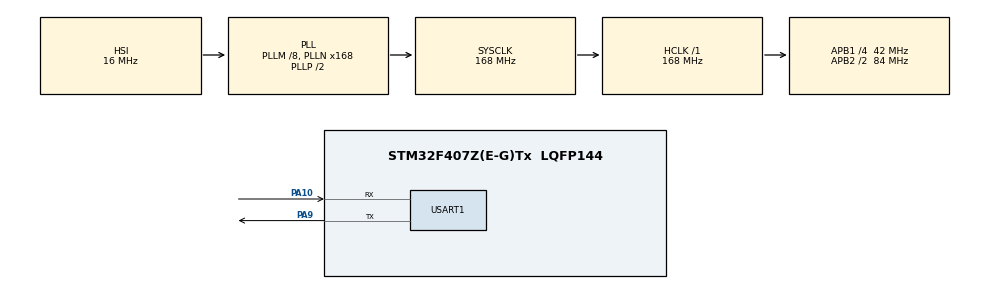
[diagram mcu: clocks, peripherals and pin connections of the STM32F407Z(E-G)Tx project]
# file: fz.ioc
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FREERTOS.BinarySemaphores01=ShellReadSem,Dynamic,NULL
FREERTOS.Mutexes01=ShellTxMut,Dynamic,NULL
FREERTOS.Queues01=UartRx,8,uint8_t,NULL,Dynamic,NULL,NULL
FREERTOS.Tasks01=defaultTask,0,128,StartDefaultTask,Default,NULL,Dynamic,NULL,NULL;ShellRead,-3,128,ShellReadEntry,Default,NULL,Dynamic,NULL,NULL
FREERTOS.configUSE_ALTERNATIVE_API=0
Mcu.Family=STM32F4
Mcu.Name=STM32F407Z(E-G)Tx
Mcu.Package=LQFP144
NVIC.PriorityGroup=NVIC_PRIORITYGROUP_4
NVIC.USART1_IRQn=true\:5\:0\:false\:false\:true\:true
PA10.Mode=Asynchronous
PA10.Signal=USART1_RX
PA9.Mode=Asynchronous
PA9.Signal=USART1_TX
PH0-OSC_IN.Mode=HSE-External-Oscillator
PH0-OSC_IN.Signal=RCC_OSC_IN
PH1-OSC_OUT.Mode=HSE-External-Oscillator
PH1-OSC_OUT.Signal=RCC_OSC_OUT
ProjectManager.HeapSize=0x200
ProjectManager.StackSize=0x400
ProjectManager.TargetToolchain=EWARM
RCC.48MHZClocksFreq_Value=84000000
RCC.AHBCLKDivider=RCC_SYSCLK_DIV1
RCC.AHBFreq_Value=168000000
RCC.APB1CLKDivider=RCC_HCLK_DIV4
RCC.APB1Freq_Value=42000000
RCC.APB1TimFreq_Value=84000000
RCC.APB2CLKDivider=RCC_HCLK_DIV2
RCC.APB2Freq_Value=84000000
RCC.APB2TimFreq_Value=168000000
RCC.ClockTypeHCLK=RCC_CLOCKTYPE_HCLK
RCC.ClockTypePCLK1=RCC_CLOCKTYPE_PCLK1
RCC.ClockTypePCLK2=RCC_CLOCKTYPE_PCLK2
RCC.ClockTypeSysClk=RCC_CLOCKTYPE_SYSCLK
RCC.CortexFreq_Value=168000000
RCC.Cortex_Div=SYSTICK_CLKSOURCE_HCLK
RCC.EnableExtClockForI2S=false
RCC.EnableHSE=true
RCC.EnableHSERTCDevisor=false
RCC.EnableLSE=false
RCC.EnableLSERTC=false
RCC.ExtClockEnable=false
RCC.HCLKFreq_Value=168000000
RCC.HSEState=RCC_HSE_ON
RCC.HSE_VALUE=8000000
RCC.HSIState=RCC_HSI_ON
RCC.HSI_VALUE=16000000
RCC.I2SEnable=false
RCC.IWDGEnable=false
RCC.LSE_VALUE=32768
RCC.LSIState=RCC_LSI_OFF
RCC.MCO1OutPutEnable=false
RCC.MCO2OutPutEnable=false
RCC.OscillatorTypeHSI=RCC_OSCILLATORTYPE_HSI
RCC.PLLM=8
RCC.PLLN=168
RCC.PLLP=RCC_PLLP_DIV2
RCC.PLLSource=RCC_PLLSOURCE_HSI
RCC.PLLState=RCC_PLL_ON
RCC.RCC_MCODiv1=RCC_MCODIV_1
RCC.RCC_MCODiv2=RCC_MCODIV_1
RCC.RCC_RTC_Clock_Source_FROM_HSE=RCC_RTCCLKSOURCE_HSE_DIV2
RCC.RNGEnable=false
RCC.RTCEnable=false
RCC.SDIOEnable=false
RCC.SYSCLKFreq_VALUE=168000000
RCC.SYSCLKSource=RCC_SYSCLKSOURCE_PLLCLK
RCC.USBFSEnable=false
RCC.USBHSEnable=false
RCC.VCOOutputFreq_Value=336000000
USART1.HwFlowCtl-Asynchronous=UART_HWCONTROL_NONE
USART1.VirtualMode=VM_ASYNC
VP_FREERTOS_VS_ENABLE.Mode=Enabled
board=fz

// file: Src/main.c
/**
  ******************************************************************************
  * File Name          : main.c
  * Description        : Main program body
  ******************************************************************************
  *
  * Copyright (c) 2017 STMicroelectronics International N.V.
  * All rights reserved.
  *
  * Redistribution and use in source and binary forms, with or without
  * modification, are permitted, provided that the following conditions are met:
  *
  * 1. Redistribution of source code must retain the above copyright notice,
  *    this list of conditions and the following disclaimer.
  * 2. Redistributions in binary form must reproduce the above copyright notice,
  *    this list of conditions and the following disclaimer in the documentation
  *    and/or other materials provided with the distribution.
  * 3. Neither the name of STMicroelectronics nor the names of other
  *    contributors to this software may be used to endorse or promote products
  *    derived from this software without specific written permission.
  * 4. This software, including modifications and/or derivative works of this
  *    software, must execute solely and exclusively on microcontroller or
  *    microprocessor devices manufactured by or for STMicroelectronics.
  * 5. Redistribution and use of this software other than as permitted under
  *    this license is void and will automatically terminate your rights under
  *    this license.
  *
  * THIS SOFTWARE IS PROVIDED BY STMICROELECTRONICS AND CONTRIBUTORS "AS IS"
  * AND ANY EXPRESS, IMPLIED OR STATUTORY WARRANTIES, INCLUDING, BUT NOT
  * LIMITED TO, THE IMPLIED WARRANTIES OF MERCHANTABILITY, FITNESS FOR A
  * PARTICULAR PURPOSE AND NON-INFRINGEMENT OF THIRD PARTY INTELLECTUAL PROPERTY
  * RIGHTS ARE DISCLAIMED TO THE FULLEST EXTENT PERMITTED BY LAW. IN NO EVENT
  * SHALL STMICROELECTRONICS OR CONTRIBUTORS BE LIABLE FOR ANY DIRECT, INDIRECT,
  * INCIDENTAL, SPECIAL, EXEMPLARY, OR CONSEQUENTIAL DAMAGES (INCLUDING, BUT NOT
  * LIMITED TO, PROCUREMENT OF SUBSTITUTE GOODS OR SERVICES; LOSS OF USE, DATA,
  * OR PROFITS; OR BUSINESS INTERRUPTION) HOWEVER CAUSED AND ON ANY THEORY OF
  * LIABILITY, WHETHER IN CONTRACT, STRICT LIABILITY, OR TORT (INCLUDING
  * NEGLIGENCE OR OTHERWISE) ARISING IN ANY WAY OUT OF THE USE OF THIS SOFTWARE,
  * EVEN IF ADVISED OF THE POSSIBILITY OF SUCH DAMAGE.
  *
  ******************************************************************************
  */
#include "main.h"
#include "stm32f4xx_hal.h"
#include "cmsis_os.h"

/* USER CODE BEGIN Includes */
#include "string.h"
#include "fzshell.h"
#include "fzshelllib.h"
/* USER CODE END Includes */

UART_HandleTypeDef huart1;

osThreadId defaultTaskHandle;
osThreadId ShellReadHandle;
osMessageQId UartRxHandle;
osMutexId ShellTxMutHandle;
osSemaphoreId ShellReadSemHandle;

/* USER CODE BEGIN PV */
/* Private variables ---------------------------------------------------------*/

/* USER CODE END PV */

void SystemClock_Config(void);
void Error_Handler(void);
static void MX_GPIO_Init(void);
static void MX_USART1_UART_Init(void);
void StartDefaultTask(void const * argument);
void ShellReadEntry(void const * argument);

/* USER CODE BEGIN PFP */
/* Private function prototypes -----------------------------------------------*/

/* USER CODE END PFP */

int main(void)
{

  /* MCU Configuration----------------------------------------------------------*/

  /* Reset of all peripherals, Initializes the Flash interface and the Systick. */
  HAL_Init();

  /* Configure the system clock */
  SystemClock_Config();

  /* Initialize all configured peripherals */
  MX_GPIO_Init();
  MX_USART1_UART_Init();

  /* USER CODE BEGIN 2 */
  uint8_t a[]="init..\r\n";
  HAL_UART_Transmit(&huart1, a,strlen(a),100);
  /* USER CODE END 2 */

  /* Create the mutex(es) */
  /* definition and creation of ShellTxMut */
  osMutexDef(ShellTxMut);
  ShellTxMutHandle = osMutexCreate(osMutex(ShellTxMut));

  /* Create the semaphores(s) */
  /* definition and creation of ShellReadSem */
  osSemaphoreDef(ShellReadSem);
  ShellReadSemHandle = osSemaphoreCreate(osSemaphore(ShellReadSem), 1);

  /* Create the thread(s) */
  /* definition and creation of defaultTask */
  osThreadDef(defaultTask, StartDefaultTask, osPriorityNormal, 0, 128);
  defaultTaskHandle = osThreadCreate(osThread(defaultTask), NULL);

  /* definition and creation of ShellRead */
  osThreadDef(ShellRead, ShellReadEntry, osPriorityIdle, 0, 128);
  ShellReadHandle = osThreadCreate(osThread(ShellRead), NULL);

  /* Create the queue(s) */
  /* definition and creation of UartRx */
  osMessageQDef(UartRx, 8, uint8_t);
  UartRxHandle = osMessageCreate(osMessageQ(UartRx), NULL);

  /* Start scheduler */
  osKernelStart();

  /* We should never get here as control is now taken by the scheduler */

  /* Infinite loop */
  while (1)
  {

  }

}

/** System Clock Configuration
*/
void SystemClock_Config(void)
{

  RCC_OscInitTypeDef RCC_OscInitStruct;
  RCC_ClkInitTypeDef RCC_ClkInitStruct;

    /**Configure the main internal regulator output voltage
    */
  __HAL_RCC_PWR_CLK_ENABLE();

  __HAL_PWR_VOLTAGESCALING_CONFIG(PWR_REGULATOR_VOLTAGE_SCALE1);

    /**Initializes the CPU, AHB and APB busses clocks
    */
  RCC_OscInitStruct.OscillatorType = RCC_OSCILLATORTYPE_HSI;
  RCC_OscInitStruct.HSIState = RCC_HSI_ON;
  RCC_OscInitStruct.HSICalibrationValue = 16;
  RCC_OscInitStruct.PLL.PLLState = RCC_PLL_ON;
  RCC_OscInitStruct.PLL.PLLSource = RCC_PLLSOURCE_HSI;
  RCC_OscInitStruct.PLL.PLLM = 8;
  RCC_OscInitStruct.PLL.PLLN = 168;
  RCC_OscInitStruct.PLL.PLLP = RCC_PLLP_DIV2;
  RCC_OscInitStruct.PLL.PLLQ = 4;
  if (HAL_RCC_OscConfig(&RCC_OscInitStruct) != HAL_OK)
  {
    Error_Handler();
  }

    /**Initializes the CPU, AHB and APB busses clocks
    */
  RCC_ClkInitStruct.ClockType = RCC_CLOCKTYPE_HCLK|RCC_CLOCKTYPE_SYSCLK
                              |RCC_CLOCKTYPE_PCLK1|RCC_CLOCKTYPE_PCLK2;
  RCC_ClkInitStruct.SYSCLKSource = RCC_SYSCLKSOURCE_PLLCLK;
  RCC_ClkInitStruct.AHBCLKDivider = RCC_SYSCLK_DIV1;
  RCC_ClkInitStruct.APB1CLKDivider = RCC_HCLK_DIV4;
  RCC_ClkInitStruct.APB2CLKDivider = RCC_HCLK_DIV2;

  if (HAL_RCC_ClockConfig(&RCC_ClkInitStruct, FLASH_LATENCY_5) != HAL_OK)
  {
    Error_Handler();
  }

    /**Configure the Systick interrupt time
    */
  HAL_SYSTICK_Config(HAL_RCC_GetHCLKFreq()/1000);

    /**Configure the Systick
    */
  HAL_SYSTICK_CLKSourceConfig(SYSTICK_CLKSOURCE_HCLK);

  /* SysTick_IRQn interrupt configuration */
  HAL_NVIC_SetPriority(SysTick_IRQn, 15, 0);
}

/* USART1 init function */
static void MX_USART1_UART_Init(void)
{

  huart1.Instance = USART1;
  huart1.Init.BaudRate = 115200;
  huart1.Init.WordLength = UART_WORDLENGTH_8B;
  huart1.Init.StopBits = UART_STOPBITS_1;
  huart1.Init.Parity = UART_PARITY_NONE;
  huart1.Init.Mode = UART_MODE_TX_RX;
  huart1.Init.HwFlowCtl = UART_HWCONTROL_NONE;
  huart1.Init.OverSampling = UART_OVERSAMPLING_16;
  if (HAL_UART_Init(&huart1) != HAL_OK)
  {
    Error_Handler();
  }

}

/** Configure pins as
        * Analog
        * Input
        * Output
        * EVENT_OUT
        * EXTI
*/
static void MX_GPIO_Init(void)
{

  /* GPIO Ports Clock Enable */
  __HAL_RCC_GPIOH_CLK_ENABLE();
  __HAL_RCC_GPIOA_CLK_ENABLE();

}

/* StartDefaultTask function */
void StartDefaultTask(void const * argument)
{

  /* USER CODE BEGIN 5 */
  /* Infinite loop */
  for(;;)
  {
    osDelay(1000);
  }
  /* USER CODE END 5 */
}

/* ShellReadEntry function */
void ShellReadEntry(void const * argument)
{
  /* USER CODE BEGIN ShellReadEntry */
  fzshell_thread();
  /* Infinite loop */
  for(;;)
  {
    osDelay(1000);
  }
  /* USER CODE END ShellReadEntry */
}

void Error_Handler(void)
{
  while(1)
  {
  }
}

/************************ (C) COPYRIGHT STMicroelectronics *****END OF FILE****/
